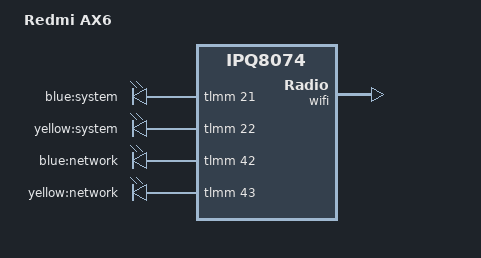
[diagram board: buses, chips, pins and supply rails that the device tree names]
// SPDX-License-Identifier: GPL-2.0-or-later OR MIT
/* Copyright (c) 2021, Zhijun You <hujy652@gmail.com> */

/dts-v1/;

#include "ipq8071-ax3600.dtsi"

/ {
	model = "Redmi AX6";
	compatible = "redmi,ax6", "qcom,ipq8074";

	leds {
		compatible = "gpio-leds";

		led_system_blue: system-blue {
			label = "blue:system";
			gpios = <&tlmm 21 GPIO_ACTIVE_HIGH>;
		};

		led_system_yellow: system-yellow {
			label = "yellow:system";
			gpios = <&tlmm 22 GPIO_ACTIVE_HIGH>;
		};

		network-blue {
			label = "blue:network";
			gpios = <&tlmm 42 GPIO_ACTIVE_HIGH>;
		};

		network-yellow {
			label = "yellow:network";
			gpios = <&tlmm 43 GPIO_ACTIVE_HIGH>;
		};
	};
};

&wifi {
	qcom,ath11k-calibration-variant = "Redmi-AX6";
};
